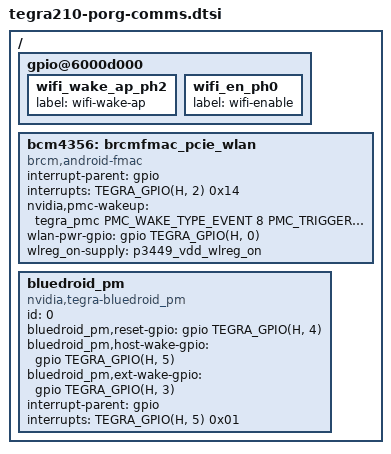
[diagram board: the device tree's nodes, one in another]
/*
 * Copyright (c) 2015-2017, NVIDIA CORPORATION.  All rights reserved.
 *
 * This program is free software; you can redistribute it and/or modify
 * it under the terms of the GNU General Public License as published by
 * the Free Software Foundation; version 2 of the License.
 *
 * This program is distributed in the hope that it will be useful, but WITHOUT
 * ANY WARRANTY; without even the implied warranty of MERCHANTABILITY or
 * FITNESS FOR A PARTICULAR PURPOSE.  See the GNU General Public License for
 * more details.
 */

#include <dt-bindings/gpio/tegra-gpio.h>
#include <dt-bindings/soc/tegra-pmc.h>

/ {
	gpio@6000d000 {
		wifi_wake_ap_ph2 {
			label = "wifi-wake-ap";
		};
		wifi_en_ph0 {
			label = "wifi-enable";
		};
	};

	bcm4356: brcmfmac_pcie_wlan {
		compatible = "brcm,android-fmac";
		interrupt-parent = <&gpio>;
		interrupts = <TEGRA_GPIO(H, 2) 0x14>;
		nvidia,pmc-wakeup = <&tegra_pmc
		PMC_WAKE_TYPE_EVENT 8 PMC_TRIGGER_TYPE_HIGH>;
		wlan-pwr-gpio = <&gpio TEGRA_GPIO(H, 0) 0>;
		wlreg_on-supply = <&p3449_vdd_wlreg_on>;
		status = "okay";
	};

	bluedroid_pm {
		compatible = "nvidia,tegra-bluedroid_pm";
		id = <0>;
		bluedroid_pm,reset-gpio = <&gpio TEGRA_GPIO(H, 4) 0>;
		bluedroid_pm,host-wake-gpio = <&gpio TEGRA_GPIO(H, 5) 0>;
		bluedroid_pm,ext-wake-gpio = <&gpio TEGRA_GPIO(H, 3) 0>;
		interrupt-parent = <&gpio>;
		interrupts = <TEGRA_GPIO(H, 5) 0x01>;
	};
};
